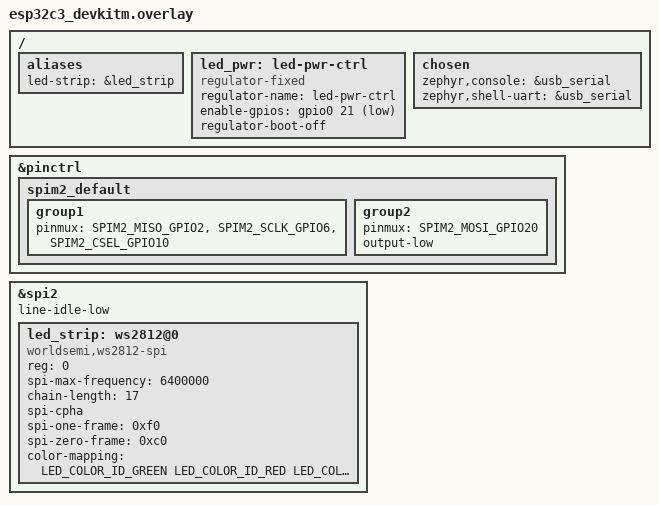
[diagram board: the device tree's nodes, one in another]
/*
 * Devicetree overlay for ZY-17W keyboard hardware
 *
 * Pin map:
 *   WS2812B per-key RGB  → SPI2 MOSI  GPIO20
 *   POW_PIN (LED gate)   → GPIO21
 *   Matrix rows          → GPIO6-10
 *   Matrix cols          → GPIO0-3
 *   EC11                 → GPIO12, GPIO13
 *   Pseudo-slider        → GPIO4, GPIO5
 *   Sleep switch         → GPIO11
 *
 * Note: devkitm UART0 uses GPIO20(RX)/GPIO21(TX) — same pins as the
 * LED data and power gate on the custom PCB.  On devkitm, either
 * comment out the WS2812B node or accept that UART0 RX won't work
 * while the LED strip is in use.  On the custom ZY-17W PCB there is
 * no conflict because the UART transceiver is not populated.
 */

#include <zephyr/dt-bindings/led/led.h>

/ {
	aliases {
		led-strip = &led_strip;
	};

	/* POW_PIN: active-low MOSFET gate for LED power */
	led_pwr: led-pwr-ctrl {
		compatible = "regulator-fixed";
		regulator-name = "led-pwr-ctrl";
		enable-gpios = <&gpio0 21 GPIO_ACTIVE_LOW>;
		regulator-boot-off;
	};

	chosen {
		zephyr,console = &usb_serial;
		zephyr,shell-uart = &usb_serial;
	};
};

/* SPI2 drives the WS2812B per-key RGB LEDs */
&pinctrl {
	spim2_default: spim2_default {
		group1 {
			pinmux = <SPIM2_MISO_GPIO2>,
				 <SPIM2_SCLK_GPIO6>,
				 <SPIM2_CSEL_GPIO10>;
		};
		group2 {
			pinmux = <SPIM2_MOSI_GPIO20>;
			output-low;
		};
	};
};

&spi2 {
	line-idle-low;

	led_strip: ws2812@0 {
		compatible = "worldsemi,ws2812-spi";
		reg = <0>;
		spi-max-frequency = <6400000>;
		chain-length = <17>;
		spi-cpha;

		/* WS2812B pulse timing via SPI byte frames */
		spi-one-frame = <0xf0>;   /* 11110000 → ~625ns high, 625ns low */
		spi-zero-frame = <0xc0>;  /* 11000000 → ~312.5ns high, 937.5ns low */
		color-mapping = <LED_COLOR_ID_GREEN
				 LED_COLOR_ID_RED
				 LED_COLOR_ID_BLUE>;
	};
};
